# ADSP-2183xW_LPC register map
Vendor: Analog Devices; Series: ADSP-2183xW_LPC; File version: 3.0.3.517
CPU: 
Registers are 32-bit, read-write, reset 0x0 unless marked. A register's access mark holds for its fields unless they carry their own. Offsets are from the block's base; [hi:lo] are bit positions; {n}, {i} and the like mark numbered series.

## CSTF0
Base 0x31108000
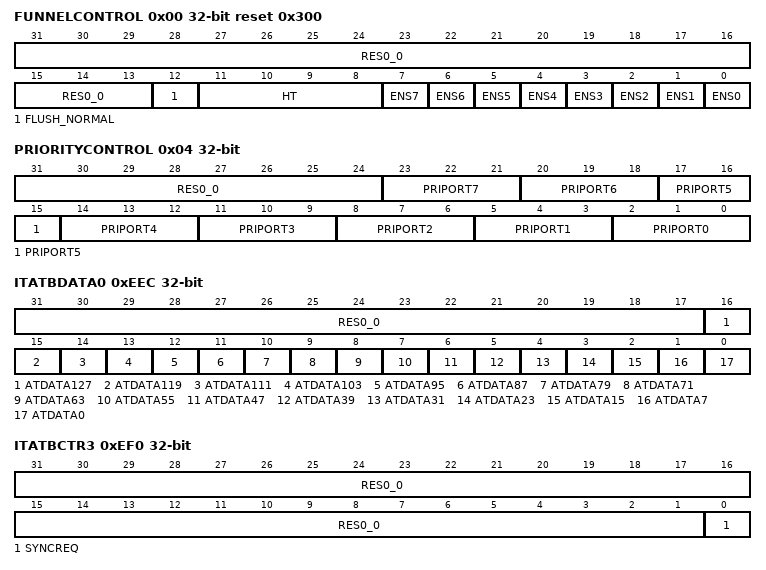
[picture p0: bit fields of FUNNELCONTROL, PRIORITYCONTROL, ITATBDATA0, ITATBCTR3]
0x00 FUNNELCONTROL reset 0x300
  [31:13] RES0_0 range 0x00000000..0x0007FFFF, [12] FLUSH_NORMAL range 0x00000000..0x00000001, [11:8] HT range 0x00000000..0x0000000F, [n] ENS{n} range 0x00000000..0x00000001 (n=0..7)
0x04 PRIORITYCONTROL
  [31:24] RES0_0 range 0x00000000..0x000000FF, [3n+2:3n] PRIPORT{n} range 0x00000000..0x00000007 (n=0..7)
0xEEC ITATBDATA0 — Integration test data register.
  [31:17] RES0_0 range 0x00000000..0x00007FFF, [16] ATDATA127 range 0x00000000..0x00000001, [15] ATDATA119 range 0x00000000..0x00000001, [14] ATDATA111 range 0x00000000..0x00000001, [13] ATDATA103 range 0x00000000..0x00000001, [12] ATDATA95 range 0x00000000..0x00000001, [11] ATDATA87 range 0x00000000..0x00000001, [10] ATDATA79 range 0x00000000..0x00000001, [9] ATDATA71 range 0x00000000..0x00000001, [8] ATDATA63 range 0x00000000..0x00000001, [7] ATDATA55 range 0x00000000..0x00000001, [6] ATDATA47 range 0x00000000..0x00000001, [5] ATDATA39 range 0x00000000..0x00000001, [4] ATDATA31 range 0x00000000..0x00000001, [3] ATDATA23 range 0x00000000..0x00000001, [2] ATDATA15 range 0x00000000..0x00000001, [1] ATDATA7 range 0x00000000..0x00000001, [0] ATDATA0 range 0x00000000..0x00000001
0xEF0 ITATBCTR3 — Integration test control register 3.
  [31:1] RES0_0 range 0x00000000..0x7FFFFFFF, [0] SYNCREQ range 0x00000000..0x00000001
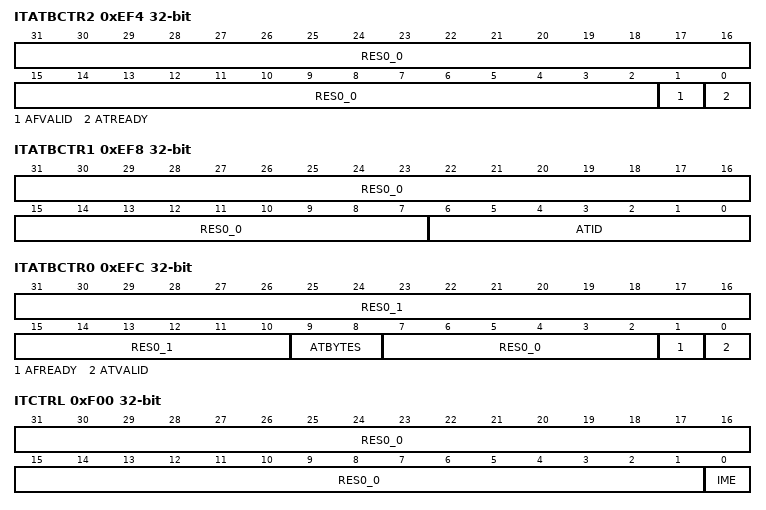
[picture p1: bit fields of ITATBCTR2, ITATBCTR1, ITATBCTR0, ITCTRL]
0xEF4 ITATBCTR2 — Integration test control register 2.
  [31:2] RES0_0 range 0x00000000..0x3FFFFFFF, [1] AFVALID range 0x00000000..0x00000001, [0] ATREADY range 0x00000000..0x00000001
0xEF8 ITATBCTR1 — Integration test control register 1.
  [31:7] RES0_0 range 0x00000000..0x01FFFFFF, [6:0] ATID range 0x00000000..0x0000007F
0xEFC ITATBCTR0 — Integration test control register 0.
  [31:10] RES0_1 range 0x00000000..0x003FFFFF, [9:8] ATBYTES range 0x00000000..0x00000003, [7:2] RES0_0 range 0x00000000..0x0000003F, [1] AFREADY range 0x00000000..0x00000001, [0] ATVALID range 0x00000000..0x00000001
0xF00 ITCTRL — Integration Mode Control Register.
  [31:1] RES0_0 range 0x00000000..0x7FFFFFFF, [0] IME range 0x00000000..0x00000001
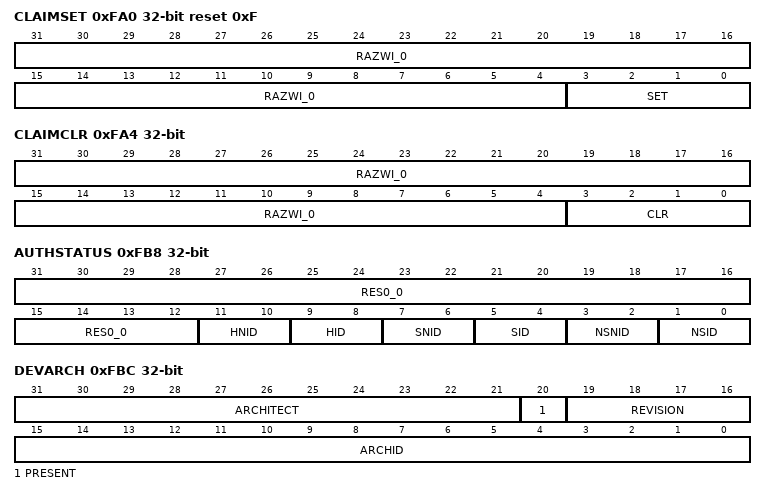
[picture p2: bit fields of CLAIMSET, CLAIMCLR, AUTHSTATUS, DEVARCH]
0xFA0 CLAIMSET reset 0xF — Claim Tag Set Register.
  [31:4] RAZWI_0 range 0x00000000..0x0FFFFFFF, [3:0] SET range 0x00000000..0x0000000F
0xFA4 CLAIMCLR — Claim Tag Clear Register.
  [31:4] RAZWI_0 range 0x00000000..0x0FFFFFFF, [3:0] CLR range 0x00000000..0x0000000F
0xFA8 DEVAFF0 — Device Affinity register 0.
  [31:0] DEVAFF0 ro
0xFAC DEVAFF1 — Device Affinity register 1.
  [31:0] DEVAFF1 ro
0xFB8 AUTHSTATUS — Authentication Status Register.
  [31:12] RES0_0 ro, [11:10] HNID ro, [9:8] HID ro, [7:6] SNID ro, [5:4] SID ro, [3:2] NSNID ro, [1:0] NSID ro
0xFBC DEVARCH — Device Architecture Register.
  [31:21] ARCHITECT ro, [20] PRESENT ro, [19:16] REVISION ro, [15:0] ARCHID ro
0xFC0 DEVID2 — Device Configuration Register 2.
  [31:0] DEVID2 ro
0xFC4 DEVID1 — Device Configuration Register 1.
  [31:0] DEVID1 ro
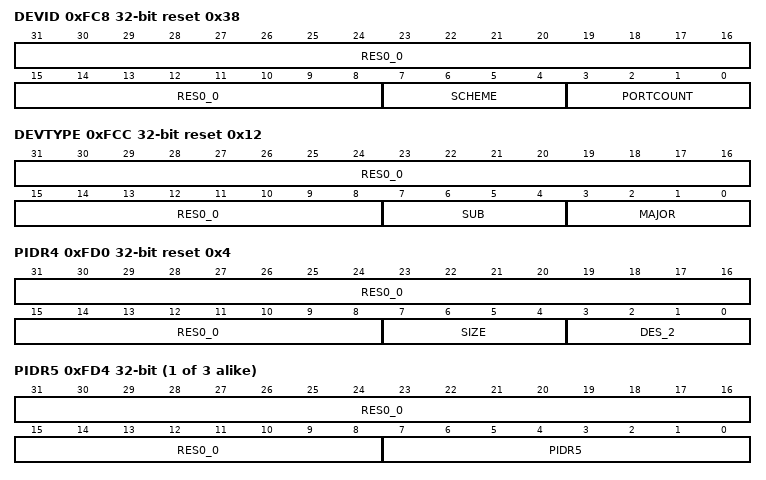
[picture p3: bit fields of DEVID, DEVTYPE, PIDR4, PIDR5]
0xFC8 DEVID reset 0x38 — Device Configuration Register.
  [31:8] RES0_0 ro, [7:4] SCHEME ro, [3:0] PORTCOUNT ro
0xFCC DEVTYPE reset 0x12 — Device Type Identifier Register.
  [31:8] RES0_0 ro, [7:4] SUB ro, [3:0] MAJOR ro
0xFD0 PIDR4 reset 0x4 — Peripheral Identification Register 4.
  [31:8] RES0_0 ro, [7:4] SIZE ro, [3:0] DES_2 ro
{0xFC0+4i} PIDR{i} (i=5..7) — Peripheral Identification Register {i}.
  [31:8] RES0_0 ro, [7:0] PIDR{i} ro
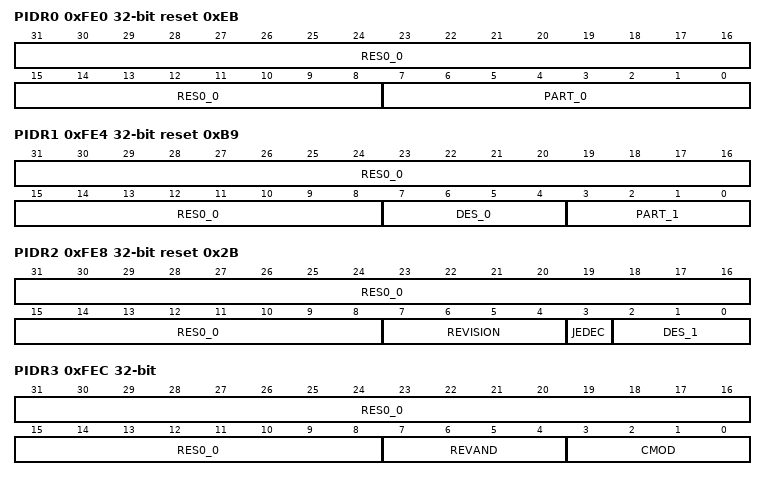
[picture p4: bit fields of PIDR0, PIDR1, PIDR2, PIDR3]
0xFE0 PIDR0 reset 0xEB — Peripheral Identification Register 0.
  [31:8] RES0_0 ro, [7:0] PART_0 ro
0xFE4 PIDR1 reset 0xB9 — Peripheral Identification Register 1.
  [31:8] RES0_0 ro, [7:4] DES_0 ro, [3:0] PART_1 ro
0xFE8 PIDR2 reset 0x2B — Peripheral Identification Register 2.
  [31:8] RES0_0 ro, [7:4] REVISION ro, [3] JEDEC ro, [2:0] DES_1 ro
0xFEC PIDR3 — Peripheral Identification Register 3.
  [31:8] RES0_0 ro, [7:4] REVAND ro, [3:0] CMOD ro
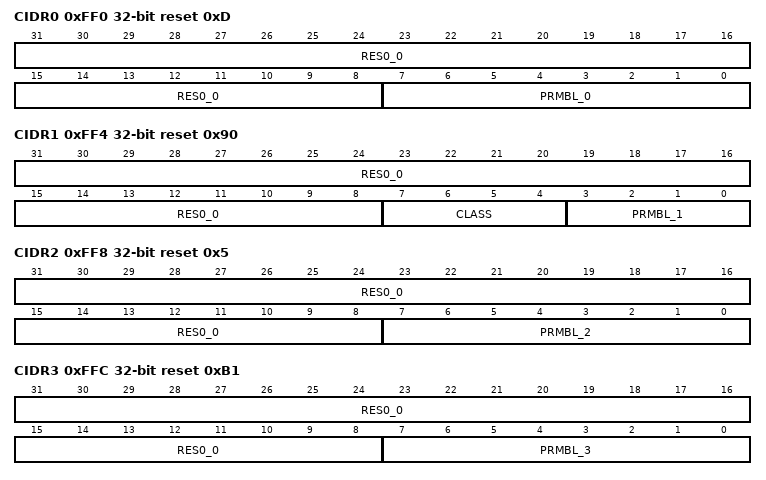
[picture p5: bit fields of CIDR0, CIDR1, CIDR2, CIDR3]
0xFF0 CIDR0 reset 0xD — Component Identification Register 0.
  [31:8] RES0_0 ro, [7:0] PRMBL_0 ro
0xFF4 CIDR1 reset 0x90 — Component Identification Register 1.
  [31:8] RES0_0 ro, [7:4] CLASS ro, [3:0] PRMBL_1 ro
0xFF8 CIDR2 reset 0x5 — Component Identification Register 2.
  [31:8] RES0_0 ro, [7:0] PRMBL_2 ro
0xFFC CIDR3 reset 0xB1 — Component Identification Register 3.
  [31:8] RES0_0 ro, [7:0] PRMBL_3 ro
